VERSION ""

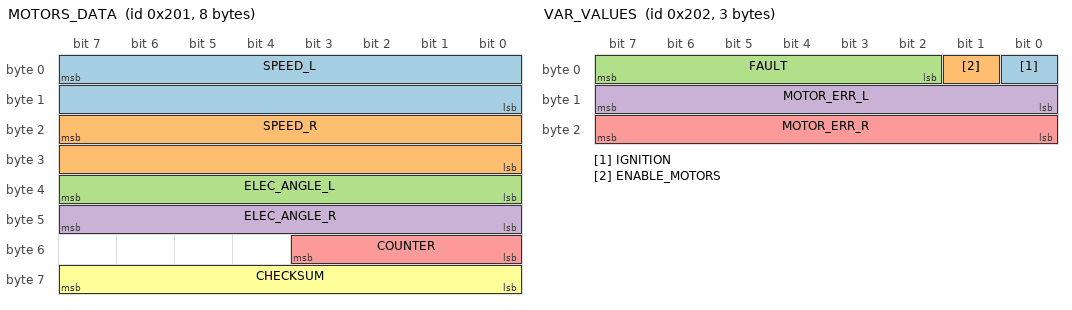
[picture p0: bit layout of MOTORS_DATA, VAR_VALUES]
BO_ 513 MOTORS_DATA: 8 XXX
  SG_ SPEED_L : 7|16@0- (1,0) [-1000|1000] "" XXX
  SG_ SPEED_R : 23|16@0- (1,0) [-1000|1000] "" XXX
  SG_ ELEC_ANGLE_L : 39|8@0+ (1,0) [0|360] "" XXX
  SG_ ELEC_ANGLE_R : 47|8@0+ (1,0) [0|360] "" XXX
  SG_ COUNTER : 51|4@0+ (1,0) [0|15] "" XXX
  SG_ CHECKSUM : 63|8@0+ (1,0) [0|255] "" XXX

BO_ 514 VAR_VALUES: 3 XXX
  SG_ IGNITION : 0|1@0+ (1,0) [0|1] "" XXX
  SG_ ENABLE_MOTORS : 1|1@0+ (1,0) [0|1] "" XXX
  SG_ FAULT : 7|6@0+ (1,0) [0|63] "" XXX
  SG_ MOTOR_ERR_L : 15|8@0+ (1,0) [0|255] "" XXX
  SG_ MOTOR_ERR_R : 23|8@0+ (1,0) [0|255] "" XXX

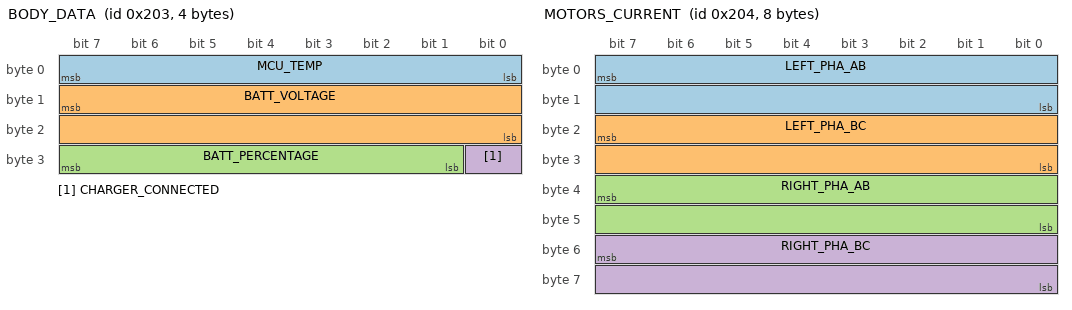
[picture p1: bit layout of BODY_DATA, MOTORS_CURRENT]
BO_ 515 BODY_DATA: 4 XXX
  SG_ MCU_TEMP : 7|8@0+ (0.1,0) [0|125] "" XXX
  SG_ BATT_VOLTAGE : 15|16@0+ (0.01,0) [0|60] "" XXX
  SG_ BATT_PERCENTAGE : 31|7@0+ (1,0) [0|100] "" XXX
  SG_ CHARGER_CONNECTED : 24|1@0+ (1,0) [0|1] "" XXX

BO_ 516 MOTORS_CURRENT: 8 XXX
  SG_ LEFT_PHA_AB : 7|16@0- (1,0) [-32768|32767] "" XXX
  SG_ LEFT_PHA_BC : 23|16@0- (1,0) [-32768|32767] "" XXX
  SG_ RIGHT_PHA_AB : 39|16@0- (1,0) [-32768|32767] "" XXX
  SG_ RIGHT_PHA_BC : 55|16@0- (1,0) [-32768|32767] "" XXX

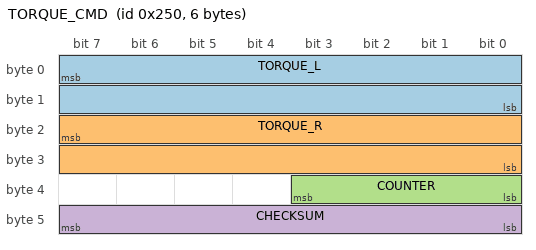
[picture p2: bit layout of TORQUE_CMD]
BO_ 592 TORQUE_CMD: 6 XXX
  SG_ TORQUE_L : 7|16@0- (1,0) [-1000|1000] "" XXX
  SG_ TORQUE_R : 23|16@0- (1,0) [-1000|1000] "" XXX
  SG_ COUNTER : 35|4@0+ (1,0) [0|15] "" XXX
  SG_ CHECKSUM : 47|8@0+ (1,0) [0|255] "" XXX
